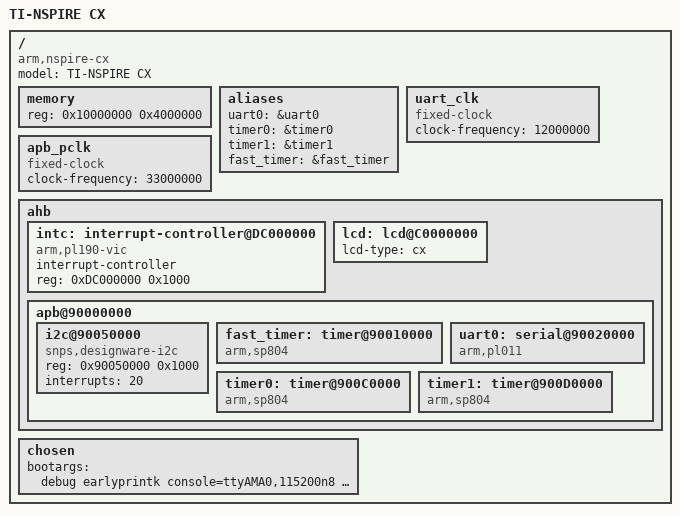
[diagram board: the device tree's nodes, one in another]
/*
 *  linux/arch/arm/boot/nspire-cx.dts
 *
 *  Copyright (C) 2012 Daniel Tang <tangrs@tangrs.id.au>
 *
 * This program is free software; you can redistribute it and/or modify
 * it under the terms of the GNU General Public License version 2, as
 * published by the Free Software Foundation.
 *
 */
/dts-v1/;

/include/ "nspire.dtsi"

/ {
	model = "TI-NSPIRE CX";
	compatible = "arm,nspire-cx";

	memory {
		device_type = "memory";
		reg = <0x10000000 0x4000000>; /* 64 MB */
	};

	aliases {
		uart0 = &uart0;
		timer0 = &timer0;
		timer1 = &timer1;
		fast_timer = &fast_timer;
	};

	uart_clk: uart_clk {
		#clock-cells = <0>;
		compatible = "fixed-clock";
		clock-frequency = <12000000>;
	};

	/* Not really a fixed clock but we'll fix this later */
	apb_pclk: apb_pclk {
		#clock-cells = <0>;
		compatible = "fixed-clock";
		clock-frequency = <33000000>;
	};

	ahb {
		#address-cells = <1>;
		#size-cells = <1>;

		intc: interrupt-controller@DC000000 {
			compatible = "arm,pl190-vic";
			interrupt-controller;
			reg = <0xDC000000 0x1000>;
			#interrupt-cells = <1>;
		};

		lcd: lcd@C0000000 {
			lcd-type = "cx";
		};

		apb@90000000 {
			#address-cells = <1>;
			#size-cells = <1>;

			i2c@90050000 {
				compatible = "snps,designware-i2c";
				reg = <0x90050000 0x1000>;
				interrupts = <20>;
			};

			fast_timer: timer@90010000 {
				compatible = "arm,sp804", "arm,primecell";
			};

			uart0: serial@90020000 {
				compatible = "arm,pl011", "arm,primecell";
			};

			timer0: timer@900C0000 {
				compatible = "arm,sp804", "arm,primecell";
			};

			timer1: timer@900D0000 {
				compatible = "arm,sp804", "arm,primecell";
			};
		};
	};
	chosen {
		bootargs = "debug earlyprintk console=ttyAMA0,115200n8 console=tty0";
	};
};
